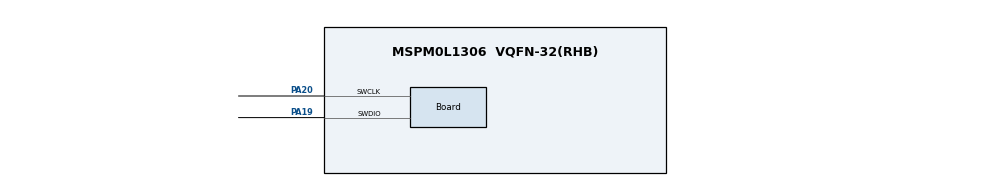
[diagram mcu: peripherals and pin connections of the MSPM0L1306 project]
//@cliArgs --device "MSPM0L130X" --package "VQFN-32(RHB)" --part "Default"
//@v2CliArgs --device "MSPM0L1306" --package "VQFN-32(RHB)"
// @cliArgs --board /ti/boards/LP_MSPM0L1306 --rtos nortos

/**
 * Import the modules used in this configuration.
 */
const ADC12  = scripting.addModule("/ti/driverlib/ADC12", {}, false);
const ADC121 = ADC12.addInstance();
const Board  = scripting.addModule("/ti/driverlib/Board");
const SYSCTL = scripting.addModule("/ti/driverlib/SYSCTL");
const VREF   = scripting.addModule("/ti/driverlib/VREF");

/**
 * Write custom configuration values to the imported modules.
 */
ADC121.$name                            = "ADC12_0";
ADC121.repeatMode                       = true;
ADC121.powerDownMode                    = "DL_ADC12_POWER_DOWN_MODE_MANUAL";
ADC121.configureDMA                     = true;
ADC121.enabledInterrupts                = ["DL_ADC12_INTERRUPT_DMA_DONE"];
ADC121.enableFIFO                       = true;
ADC121.adcMem0vref                      = "VREF";
ADC121.sampleTime1                      = "0";
ADC121.adcMem0chansel                   = "DL_ADC12_INPUT_CHAN_2";
ADC121.sampleTime0                      = "10 us";
ADC121.enabledDMATriggers               = ["DL_ADC12_DMA_MEM3_RESULT_LOADED"];
ADC121.sampCnt                          = 2;
ADC121.peripheral.$assign               = "ADC0";
ADC121.peripheral.adcPin2.$assign       = "PA25";
ADC121.DMA_CHANNEL.$name                = "DMA_CH0";
ADC121.DMA_CHANNEL.addressMode          = "f2b";
ADC121.DMA_CHANNEL.enableEarlyInterrupt = true;
ADC121.DMA_CHANNEL.enableInterrupt      = true;
ADC121.DMA_CHANNEL.earlyIntThresh       = "HALF";
ADC121.DMA_CHANNEL.peripheral.$assign   = "DMA_CH0";
ADC121.adcPin2Config.$name              = "ti_driverlib_gpio_GPIOPinGeneric0";

Board.peripheral.$assign          = "DEBUGSS";
Board.peripheral.swclkPin.$assign = "PA20";
Board.peripheral.swdioPin.$assign = "PA19";

SYSCTL.peripheral.$assign = "SYSCTL";

VREF.advClockConfigEnable = true;
VREF.checkVREFReady       = true;
VREF.basicIntVolt         = "DL_VREF_BUFCONFIG_OUTPUT_2_5V";
VREF.peripheral.$assign   = "VREF";
